# DECODER0_MSVDX_VEC_MPEG4 register map
Vendor: Texas Instruments
Peripheral module from a debugger description file (folder J7ES).
Registers are 32-bit, read-write, reset 0x0 unless marked. A register's access mark holds for its fields unless they carry their own. Offsets are as the file gives them; lines under a group give offsets from that group; [hi:lo] are bit positions; {n}, {i} and the like mark numbered series; 'fields as' and 'values as' point back to an identical list; <NAME> marks a mode.

## DECODER0_MSVDX_VEC_MPEG4
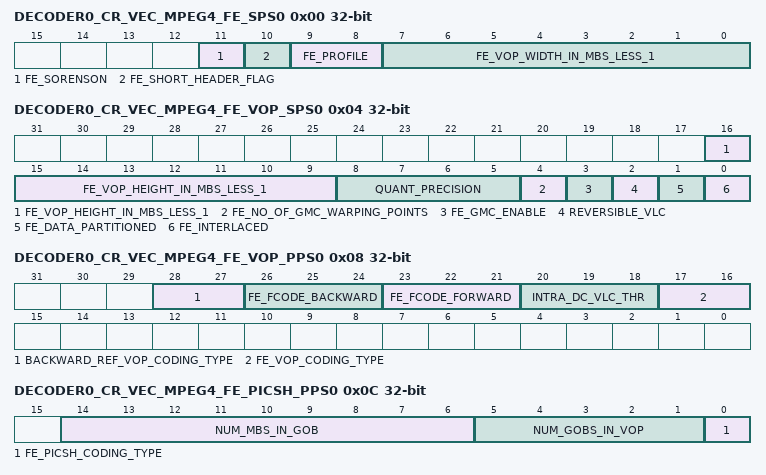
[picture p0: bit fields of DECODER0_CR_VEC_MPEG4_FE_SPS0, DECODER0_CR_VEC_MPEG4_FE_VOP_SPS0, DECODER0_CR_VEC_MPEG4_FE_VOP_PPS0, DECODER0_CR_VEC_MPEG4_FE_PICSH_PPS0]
0x00 DECODER0_CR_VEC_MPEG4_FE_SPS0 — End MPEG4 sequence-level parameters (from a Sequence Parameter Set) required for decoding macroblocks
  [11] FE_SORENSON — Should be set if this is the Sorenson version of H.263
  [10] FE_SHORT_HEADER_FLAG — The short_video_header is an internal flag which is set to 1 when an abbreviated header format is used for the VOP
  [9:8] FE_PROFILE
  [7:0] FE_VOP_WIDTH_IN_MBS_LESS_1 — size, in macroblock units minus 1, of the rectangle that includes the VOP
0x04 DECODER0_CR_VEC_MPEG4_FE_VOP_SPS0 — End MPEG4 sequence-level parameters (from a Sequence Parameter Set) required for decoding macroblocks in a VOP
  [16:9] FE_VOP_HEIGHT_IN_MBS_LESS_1 — of picture in MBs minus 1
  [8:5] QUANT_PRECISION — Number of bits used to represent quantiser scales
  [4] FE_NO_OF_GMC_WARPING_POINTS — According to the mpeg4 spec this is a
  [3] FE_GMC_ENABLE — This is a
  [2] REVERSIBLE_VLC — When set to 1 indicates that the macroblock data is rearranged differently, specifically, motion vector data is separated from the texture data
  [1] FE_DATA_PARTITIONED — When set to 1 indicates that the macroblock data is rearranged differently, specifically, motion vector data is separated from the texture data
  [0] FE_INTERLACED — When set to 1 indicates that the VOPs associated with the VOL may contain interlaced video
0x08 DECODER0_CR_VEC_MPEG4_FE_VOP_PPS0 — End MPEG4 picture-level parameters (from a Picture Parameter Set) required for decoding macroblocks in a VOP
  [28:27] BACKWARD_REF_VOP_CODING_TYPE — vop_coding_type of the backward reference VOP
  [26:24] FE_FCODE_BACKWARD — This is a
  [23:21] FE_FCODE_FORWARD — This is a
  [20:18] INTRA_DC_VLC_THR — Specifies a threshold value of quantiser scale used to switch between two VLC's for coding of Intra DC coefficients
  [17:16] FE_VOP_CODING_TYPE — Identifies whether a picture is an intra-coded [I], predictive-coded [P], bidirectionally predictive-coded [B] or sprite coded [S]
0x0C DECODER0_CR_VEC_MPEG4_FE_PICSH_PPS0 — End MPEG4 picture-level parameters (from a Picture Parameter Set) required for decoding macroblocks in a picture of short-header mode
  [14:6] NUM_MBS_IN_GOB — Fixed number of macroblocks in the VOP
  [5:1] NUM_GOBS_IN_VOP — Number of GOBs in the VOP
  [0] FE_PICSH_CODING_TYPE — Identifies whether a picture woth short header is an intra-coded [I] or predictive-coded [P]
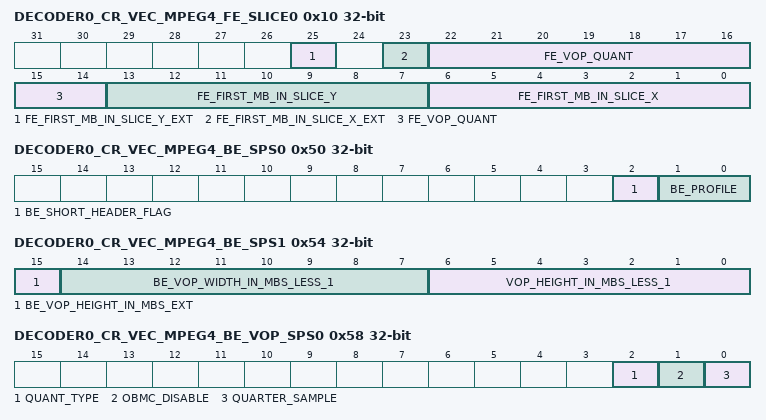
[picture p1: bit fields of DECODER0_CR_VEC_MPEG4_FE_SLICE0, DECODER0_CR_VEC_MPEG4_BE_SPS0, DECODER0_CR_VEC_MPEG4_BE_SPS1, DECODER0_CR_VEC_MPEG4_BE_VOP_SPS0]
0x10 DECODER0_CR_VEC_MPEG4_FE_SLICE0 — End MPEG4 slice-level parameters required for decoding macroblocks
  [25] FE_FIRST_MB_IN_SLICE_Y_EXT — Extension of first_mb_in_slice_y to allow 4kx4k image size
  [23] FE_FIRST_MB_IN_SLICE_X_EXT — Extension of first_mb_in_slice_x to allow 4kx4k image size
  [22:14] FE_VOP_QUANT — Specifies the absolute value of quantiser scale to be used for inverse quantising the macroblocks
  [13:7] FE_FIRST_MB_IN_SLICE_Y — Vertical coordinate of the first macroblock of the slice
  [6:0] FE_FIRST_MB_IN_SLICE_X — Horizontal coordinate of the first macroblock of the slice
0x14 DECODER0_CR_VEC_MPEG4_FE_PARSER_VLR_BASE_ADDR
  [27:18] FE_PARSER_VLR_BASE_ADDR — Base address pointer within VEC Local RAM for the MPEG4 parser to store not_coded bits.
0x18 DECODER0_CR_VEC_MPEG4_FE_DATAPARTITION0_BASE_ADDR
  [31:12] FE_DATAPARTITION0_BASE_ADDR — The base address in host memory to be used for storing phase 0 parameters when decoding a Data Partitioned stream
0x1C DECODER0_CR_VEC_MPEG4_FE_DATAPARTITION1_BASE_ADDR
  [31:12] FE_DATAPARTITION1_BASE_ADDR — The base address in host memory to be used for storing phase 1 parameters when decoding a Data Partitioned stream 1 s16
0x20 DECODER0_CR_VEC_MPEG4_FE_DATAPARTITION_VLR_BASE_ADDR
  [11:0] FE_DATAPARTITION_VLR_BASE_ADDR — The base address in VEC Local RAM to be used by VLRIF for storing phase 0 and phase 1 parameters when decoding a Data Partitioned stream
0x50 DECODER0_CR_VEC_MPEG4_BE_SPS0 — Back End MPEG4 sequence-level parameters (from a Sequence Parameter Set) required for decoding macroblocks
  [2] BE_SHORT_HEADER_FLAG — The short_video_header is an internal flag which is set to 1 when an abbreviated header format is used for the VOP
  [1:0] BE_PROFILE
0x54 DECODER0_CR_VEC_MPEG4_BE_SPS1 — End MPEG4 sequence-level parameters (from a Sequence Parameter Set) required for decoding macroblocks
  [15] BE_VOP_HEIGHT_IN_MBS_EXT — Extension for BE vop_height_in_mbs_less_1 to allow for 4k x 4k resolution
  [14:7] BE_VOP_WIDTH_IN_MBS_LESS_1 — size, in macroblock units minus 1, of the rectangle that includes the VOP
  [6:0] VOP_HEIGHT_IN_MBS_LESS_1 — Vertical size, in macroblock units minus 1, of the rectangle that includes the VOP
0x58 DECODER0_CR_VEC_MPEG4_BE_VOP_SPS0 — End MPEG4 sequence-level parameters (from a Sequence Parameter Set) required for decoding macroblocks in a VOP
  [2] QUANT_TYPE — This is a one-bit flag which when set to '1' indicates that the first inverse quantisation method is used for inverse quantisation of the DCT coefficients, and when set to '0' indicates that the second inverse quantisation method is used
  [1] OBMC_DISABLE — This is a one-bit flag which when set to '1' disables overlapped block motion compensation
  [0] QUARTER_SAMPLE — This is a one-bit flag which when set to '0' indicates that half sample mode and when set to '1' indicates that quarter sample mode shall be used for motion compensation of the luminance component
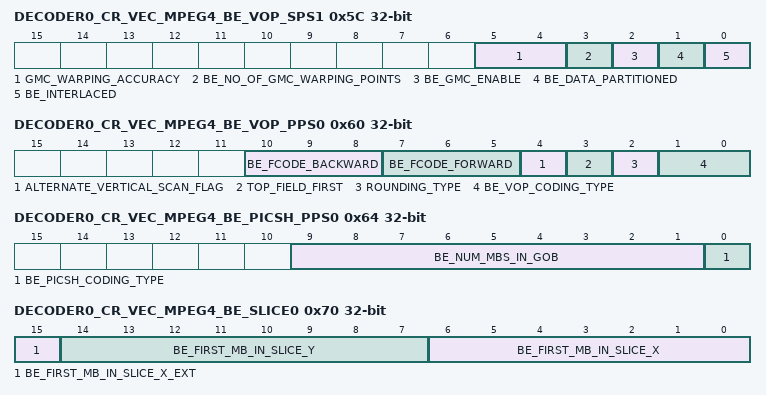
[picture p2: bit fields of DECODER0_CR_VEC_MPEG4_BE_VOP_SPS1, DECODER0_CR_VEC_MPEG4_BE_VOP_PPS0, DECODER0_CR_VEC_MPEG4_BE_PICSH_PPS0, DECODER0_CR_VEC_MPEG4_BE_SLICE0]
0x5C DECODER0_CR_VEC_MPEG4_BE_VOP_SPS1 — End MPEG4 sequence-level parameters (from a Sequence Parameter Set) required for decoding macroblocks in a VOP
  [5:4] GMC_WARPING_ACCURACY — This is a
  [3] BE_NO_OF_GMC_WARPING_POINTS — According to the mpeg4 spec this is a
  [2] BE_GMC_ENABLE — This is a
  [1] BE_DATA_PARTITIONED — When set to 1 indicates that the macroblock data is rearranged
  [0] BE_INTERLACED — When set to 1 indicates that the VOPs associated with the VOL may contain interlaced video
0x60 DECODER0_CR_VEC_MPEG4_BE_VOP_PPS0 — End MPEG4 picture-level parameters (from a Picture Parameter Set) required for decoding macroblocks in a VOP
  [10:8] BE_FCODE_BACKWARD — This is a
  [7:5] BE_FCODE_FORWARD — This is a
  [4] ALTERNATE_VERTICAL_SCAN_FLAG — This is a
  [3] TOP_FIELD_FIRST — This is a
  [2] ROUNDING_TYPE — This is a one-bit flag which signals the value of the parameter rounding_control used for pixel value interpolation in motion compensation for P- and S[GMC]- VOPs.
  [1:0] BE_VOP_CODING_TYPE — The vop_coding_type identifies whether a VOP is an intra-coded VOP [I], predictive-coded VOP [P], bidirectionally predictive-coded VOP [B] or sprite coded VOP [S]
0x64 DECODER0_CR_VEC_MPEG4_BE_PICSH_PPS0 — End MPEG4 picture-level parameters (from a Picture Parameter Set) required for decoding macroblocks from a picture in short-header mode
  [9:1] BE_NUM_MBS_IN_GOB — Fixed number of macroblocks in the VOP
  [0] BE_PICSH_CODING_TYPE — Identifies whether a picture woth short header is an intra-coded [I] or predictive-coded [P]
0x68 DECODER0_CR_VEC_MPEG4_BE_GMC_X — End MPEG4 GMC MVs required for decoding macroblocks
  [13:0] GMC_X — Horizontal GMC MV Component
0x6C DECODER0_CR_VEC_MPEG4_BE_GMC_Y — End MPEG4 GMC MVs required for decoding macroblocks
  [13:0] GMC_Y — Vertical GMC MV Component
0x70 DECODER0_CR_VEC_MPEG4_BE_SLICE0 — End MPEG4 slice-level parameters required for decoding macroblocks
  [15] BE_FIRST_MB_IN_SLICE_X_EXT — Extension of BE_FIRST_MB_IN_SLICE_X to allow for 4k x 4k resolutions
  [14:7] BE_FIRST_MB_IN_SLICE_Y — coordinate of the first macroblock of the slice
  [6:0] BE_FIRST_MB_IN_SLICE_X — Horizontal coordinate of the first macroblock of the slice
0x74 DECODER0_CR_VEC_MPEG4_BE_VOP_TRB — info (No delta)\pard
  [15:0] BE_TRB — TRB : Temporal distance between current VOP and past anchor VOP
0x78 DECODER0_CR_VEC_MPEG4_BE_VOP_TRD — info (No delta)
  [15:0] BE_TRD — Temporal distance between past anchor VOP and the future anchor VOP.
0xE4 DECODER0_CR_VEC_MPEG4_BE_DATAPARTITION0_BASE_ADDR
  [31:12] BE_DATAPARTITION0_BASE_ADDR — The base address in host memory to be used for loading back phase 0 parameters when decoding a Data Partitioned stream
0xE8 DECODER0_CR_VEC_MPEG4_BE_DATAPARTITION1_BASE_ADDR
  [31:12] BE_DATAPARTITION1_BASE_ADDR — The base address in host memory to be used for loading back phase 1 parameters when decoding a Data Partitioned stream
0xEC DECODER0_CR_VEC_MPEG4_BE_PARAM_BASE_ADDR
  [31:12] PARAM_BASE_ADDRESS — Base address for the memory to store MB parameters
0xF0 DECODER0_CR_VEC_MPEG4_BE_DATAPARTITION_VLR_BASE_ADDR
  [11:0] BE_DATAPARTITION_VLR_BASE_ADDR — The base address in VEC Local RAM to be used for loading back phase 0 and phase 1 parameters when decoding a Data Partitioned stream
0xF8 DECODER0_CR_VEC_MPEG4_BE_COLPARAM_BASE_ADDR
  [31:12] COLPARAM_BASE_ADDRESS — Base address for the memory to access co-located MB parameters
